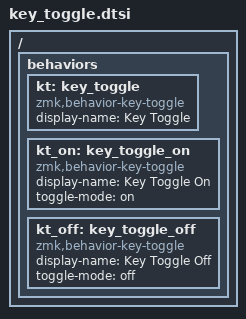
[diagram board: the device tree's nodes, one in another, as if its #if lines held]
/*
 * Copyright (c) 2022 The ZMK Contributors
 *
 * SPDX-License-Identifier: MIT
 */

#include <dt-bindings/zmk/behaviors.h>

/ {
    behaviors {
#if ZMK_BEHAVIOR_OMIT(KT)
    /omit-if-no-ref/
#endif
        kt: key_toggle {
            compatible = "zmk,behavior-key-toggle";
            #binding-cells = <1>;
            display-name = "Key Toggle";
        };

#if ZMK_BEHAVIOR_OMIT(KT_ON)
        /omit-if-no-ref/
#endif
        kt_on: key_toggle_on {
            compatible = "zmk,behavior-key-toggle";
            #binding-cells = <1>;
            display-name = "Key Toggle On";
            toggle-mode = "on";
        };

#if ZMK_BEHAVIOR_OMIT(KT_OFF)
        /omit-if-no-ref/
#endif
        kt_off: key_toggle_off {
            compatible = "zmk,behavior-key-toggle";
            #binding-cells = <1>;
            display-name = "Key Toggle Off";
            toggle-mode = "off";
        };
    };
};
